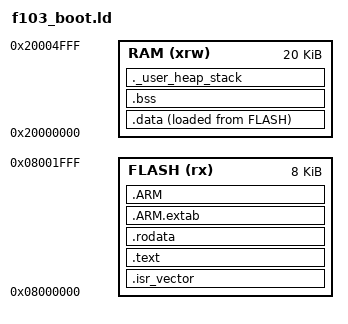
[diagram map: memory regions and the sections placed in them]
/*
 * 阶段 8：F103 IAP bootloader 链接脚本
 * FLASH 0x08000000 8KB（与 app 的 0x08002000 起始严格分隔）
 * RAM   0x20000000 20KB
 */
ENTRY(Reset_Handler)

MEMORY
{
  RAM   (xrw) : ORIGIN = 0x20000000, LENGTH = 20K
  FLASH (rx)  : ORIGIN = 0x08000000, LENGTH = 8K
}

_estack = ORIGIN(RAM) + LENGTH(RAM);

_Min_Stack_Size = 0x400;

SECTIONS
{
  .isr_vector :
  {
    . = ALIGN(4);
    KEEP(*(.isr_vector))
    . = ALIGN(4);
  } >FLASH

  .text :
  {
    . = ALIGN(4);
    *(.text)
    *(.text*)
    *(.glue_7)
    *(.glue_7t)
    *(.eh_frame)
    KEEP(*(.init))
    KEEP(*(.fini))
    . = ALIGN(4);
  } >FLASH

  .rodata :
  {
    . = ALIGN(4);
    *(.rodata)
    *(.rodata*)
    . = ALIGN(4);
  } >FLASH

  .ARM.extab (READONLY) :
  {
    . = ALIGN(4);
    *(.ARM.extab* .gnu.linkonce.armextab.*)
    . = ALIGN(4);
  } >FLASH

  .ARM (READONLY) :
  {
    . = ALIGN(4);
    __exidx_start = .;
    *(.ARM.exidx*)
    __exidx_end = .;
    . = ALIGN(4);
  } >FLASH

  _sidata = LOADADDR(.data);

  .data :
  {
    . = ALIGN(4);
    _sdata = .;
    *(.data)
    *(.data*)
    *(.RamFunc)
    *(.RamFunc*)
    . = ALIGN(4);
    _edata = .;
  } >RAM AT> FLASH

  .bss (NOLOAD) :
  {
    . = ALIGN(4);
    _sbss = .;
    *(.bss)
    *(.bss*)
    *(COMMON)
    . = ALIGN(4);
    _ebss = .;
  } >RAM

  ._user_heap_stack (NOLOAD) :
  {
    . = ALIGN(8);
    . = . + _Min_Stack_Size;
    . = ALIGN(8);
  } >RAM

  /DISCARD/ :
  {
    *(.ARM.exidx*)
  }

  ASSERT(LOADADDR(.data) + SIZEOF(.data) <= ORIGIN(FLASH) + LENGTH(FLASH),
         "bootloader exceeds 8KB flash budget")
}
